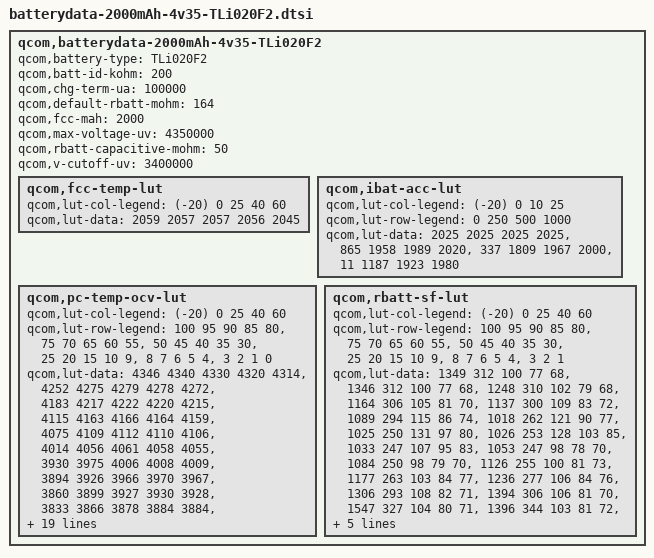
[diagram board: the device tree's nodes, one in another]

qcom,batterydata-2000mAh-4v35-TLi020F2 {
        qcom,battery-type = "TLi020F2";
        qcom,batt-id-kohm = <200>;
        qcom,chg-term-ua = <100000>;
        qcom,default-rbatt-mohm = <164>;
        qcom,fcc-mah = <2000>;
        qcom,max-voltage-uv = <4350000>;
        qcom,rbatt-capacitive-mohm = <50>;
        qcom,v-cutoff-uv = <3400000>;

        qcom,fcc-temp-lut {
                qcom,lut-col-legend = <(-20) 0 25 40 60>;
                qcom,lut-data = <2059 2057 2057 2056 2045>;
        };

        qcom,ibat-acc-lut {
                qcom,lut-col-legend = <(-20) 0 10 25>;
                qcom,lut-row-legend = <0 250 500 1000>;
                qcom,lut-data = <2025 2025 2025 2025>,
				<865 1958 1989 2020>,
				<337 1809 1967 2000>,
				<11 1187 1923 1980>;
        };

        qcom,pc-temp-ocv-lut {
                qcom,lut-col-legend = <(-20) 0 25 40 60>;
                qcom,lut-row-legend = <100 95 90 85 80>,
                                        <75 70 65 60 55>,
                                        <50 45 40 35 30>,
                                        <25 20 15 10 9>,
                                        <8 7 6 5 4>,
                                        <3 2 1 0>;
                qcom,lut-data =  <4346 4340 4330	4320 4314>,
				<4252 4275 4279	4278 4272>,
				<4183 4217 4222	4220 4215>,
				<4115 4163 4166	4164 4159>,
				<4075 4109 4112	4110 4106>,
				<4014 4056 4061	4058 4055>,
				<3930 3975 4006	4008 4009>,
				<3894 3926 3966	3970 3967>,
				<3860 3899 3927	3930 3928>,
				<3833 3866 3878	3884 3884>,
				<3813 3838 3842	3843 3842>,
				<3797 3814 3818	3818 3817>,
				<3782 3795 3799	3799 3798>,
				<3768 3781 3784	3783 3782>,
				<3755 3771 3773	3769 3765>,
				<3741 3759 3762	3754 3741>,
				<3726 3740 3744	3734 3719>,
				<3705 3718 3712	3703 3691>,
				<3675 3701 3689	3681 3669>,
				<3666 3698 3688	3680 3668>,
				<3655 3695 3687	3679 3667>,
				<3640 3691 3685	3677 3665>,
				<3623 3685 3681	3672 3658>,
				<3600 3670 3667	3651 3633>,
				<3567 3638 3626	3606 3584>,
				<3508 3573 3554	3532 3514>,
				<3443 3500 3473	3447 3413>,
				<3318 3368 3346	3306 3277>,
				<3000 3000 3000	3000 3000>;
        };

        qcom,rbatt-sf-lut {
                qcom,lut-col-legend = <(-20) 0 25 40 60>;
                qcom,lut-row-legend = <100 95 90 85 80>,
                                        <75 70 65 60 55>,
                                        <50 45 40 35 30>,
                                        <25 20 15 10 9>,
                                        <8 7 6 5 4>,
                                        <3 2 1>;
                qcom,lut-data = <1349 312 100 77 68>,
				<1346 312 100 77 68>,
				<1248 310 102 79 68>,
				<1164 306 105 81 70>,
				<1137 300 109 83 72>,
				<1089 294 115 86 74>,
				<1018 262 121 90 77>,
				<1025 250 131 97 80>,
				<1026 253 128 103 85>,
				<1033 247 107 95 83>,
				<1053 247 98 78	70>,
				<1084 250 98 79	70>,
				<1126 255 100 81 73>,
				<1177 263 103 84 77>,
				<1236 277 106 84 76>,
				<1306 293 108 82 71>,
				<1394 306 106 81 70>,
				<1547 327 104 80 71>,
				<1396 344 103 81 72>,
				<1447 359 106 84 73>,
				<1547 375 110 86 76>,
				<1700 393 115 90 79>,
				<1924 415 120 93 81>,
				<2175 433 123 90 76>,
				<2535 448 118 87 76>,
				<3870 526 132 101 86>,
				<5388 626 153 122 125>,
				<10776 702 207 176 251>;
        };
};
